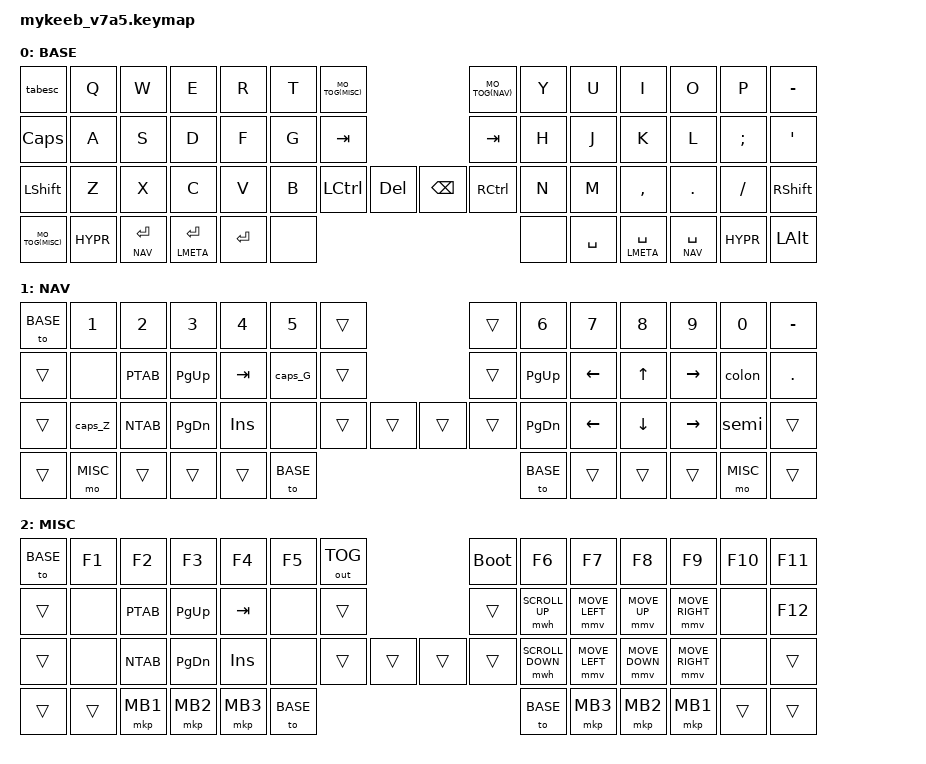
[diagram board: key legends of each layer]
#include <behaviors.dtsi>
#include <dt-bindings/zmk/keys.h>
#include <dt-bindings/zmk/bt.h>
#include <dt-bindings/zmk/outputs.h>
#include <dt-bindings/zmk/mouse.h>


//┏━━━━━━━━━━━━━━━━━━━━━━━━━━━━━━━━━━━━━━━━━━━━━━━━━━━━━━━━━━━━━━━━━━━━━━━━━━━━━━┓
//┃    this is expecting NEO 2.0 layout to be configured                         ┃
//┃    - it has some 7th row keys, to allow for y and ß                          ┃
//┃    - especially the macros for special characters use caps as an modifier    ┃
//┗━━━━━━━━━━━━━━━━━━━━━━━━━━━━━━━━━━━━━━━━━━━━━━━━━━━━━━━━━━━━━━━━━━━━━━━━━━━━━━┛


//┏━━━━━━━━━━━━━━━━━━━━━━━━━━━━━━━━━━━━━━━━━━━━━━━━━━━━━━━━━━━━━━━━━━━━━━━━━━━━━━┓
//┃    defines and macros                                                        ┃
#define PTAB LC(PG_UP)
#define NTAB LC(PG_DN)
// KC_MEH 		Left Control, Shift and Alt
#define MEH  LC(LS(LALT))
// KC_HYPR 		Left Control, Shift, Alt and GUI
#define HYPR LC(LS(LA(LGUI)))

// Macro to apply momentary-layer-on-hold/toggle-layer-on-tap to a specific layer
#define MO_TOG(layer) &mo_tog layer layer

#define CAPS_MACRO(name,key) \
    name: name { \
            label = ZMK_MACRO_STRINGIFY(ZM_ ## name); \
            compatible = "zmk,behavior-macro"; \
            #binding-cells = <0>; \
            bindings = <&macro_press &kp CAPS> , <&macro_tap &kp key >  , <&macro_release &kp CAPS> ; \
        };

#define XXX &none
#define ___ &trans
//┗━━━━━━━━━━━━━━━━━━━━━━━━━━━━━━━━━━━━━━━━━━━━━━━━━━━━━━━━━━━━━━━━━━━━━━━━━━━━━━┛

//┏━━━━━━━━━━━━━━━━━━━━━━━━━━━━━━━━━━━━━━━━━━━━━━━━━━━━━━━━━━━━━━━━━━━━━━━━━━━━━━┓
//┃    mouse stuff                                                               ┃
//┃    based on  https://github.com/urob/zmk-config/blob/main/config/mouse.dtsi  ┃
&mmv {
  acceleration-exponent = <1>;      // 1
  time-to-max-speed-ms = <1500>;    // 40
  delay-ms = <0>;                   // 0
};

&mwh {
  acceleration-exponent = <1>;      // 0
  time-to-max-speed-ms = <5000>;    // 40
  delay-ms = <0>;                   // 10
};

#define U_MOUSE_MOVE_MAX 1250       // 600
#define U_MOUSE_SCROLL_MAX 100      // 10

#undef MOVE_UP
#undef MOVE_DOWN
#undef MOVE_LEFT
#undef MOVE_RIGHT
#define MOVE_UP MOVE_VERT(-U_MOUSE_MOVE_MAX)
#define MOVE_DOWN MOVE_VERT(U_MOUSE_MOVE_MAX)
#define MOVE_LEFT MOVE_HOR(-U_MOUSE_MOVE_MAX)
#define MOVE_RIGHT MOVE_HOR(U_MOUSE_MOVE_MAX)

#undef SCROLL_UP
#undef SCROLL_DOWN
#undef SCROLL_LEFT
#undef SCROLL_RIGHT
#define SCROLL_UP SCROLL_VERT(U_MOUSE_SCROLL_MAX)
#define SCROLL_DOWN SCROLL_VERT(-U_MOUSE_SCROLL_MAX)
#define SCROLL_LEFT SCROLL_HOR(-U_MOUSE_SCROLL_MAX)
#define SCROLL_RIGHT SCROLL_HOR(U_MOUSE_SCROLL_MAX)

#define U_BTN1 &mkp MB1
#define U_BTN2 &mkp MB2
#define U_BTN3 &mkp MB3
#define U_MS_U &mmv MOVE_UP
#define U_MS_D &mmv MOVE_DOWN
#define U_MS_L &mmv MOVE_LEFT
#define U_MS_R &mmv MOVE_RIGHT
#define U_WH_U &mwh SCROLL_UP
#define U_WH_D &mwh SCROLL_DOWN
#define U_WH_L &mwh SCROLL_LEFT
#define U_WH_R &mwh SCROLL_RIGHT
//┗━━━━━━━━━━━━━━━━━━━━━━━━━━━━━━━━━━━━━━━━━━━━━━━━━━━━━━━━━━━━━━━━━━━━━━━━━━━━━━┛

//┏━━━━━━━━━━━━━━━━━━━━━━━━━━━━━━━━━━━━━━━━━━━━━━━━━━━━━━━━━━━━━━━━━━━━━━━━━━━━━━┓
//┃    layers                                                                    ┃
#define BASE 0
#define NAV  1
#define MISC 2
// #define SYMB 3
//┗━━━━━━━━━━━━━━━━━━━━━━━━━━━━━━━━━━━━━━━━━━━━━━━━━━━━━━━━━━━━━━━━━━━━━━━━━━━━━━┛

&sl {
    release-after-ms = <2000>;
};

/ {
    behaviors {
        // This is mod-tap with the "balanced" flavor.
        // Improves the '&mt RCTRL SPACE' behavior when typing quickly.
        bmt: balanced_mod_tap {
            compatible = "zmk,behavior-hold-tap";
            label = "MOD_TAP";
            #binding-cells = <2>;
            flavor = "balanced";
            tapping-term-ms = <200>;
            bindings = <&kp>, <&kp>;
        };
        skq: sticky_key_quick_release {
            compatible = "zmk,behavior-sticky-key";
            label = "STICKY_KEY_QUICK_RELEASE";
            #binding-cells = <1>;
            bindings = <&kp>;
            release-after-ms = <1000>;
            quick-release;
            ignore-modifiers;
        };
        mo_tog: behavior_mo_tog {
            compatible = "zmk,behavior-hold-tap";
            label = "mo_tog";
            #binding-cells = <2>;
            flavor = "hold-preferred";
            tapping-term-ms = <200>;
            bindings = <&mo>, <&tog>;
        };
        tabesc: tab_escape {
            compatible = "zmk,behavior-mod-morph";
            label = "TAB_ESCAPE";
            #binding-cells = <0>;
            bindings = <&kp ESC>, <&kp TAB>;
            mods = <(MOD_LGUI|MOD_LSFT|MOD_RGUI|MOD_RSFT)>;
        };
    };

    macros {
        CAPS_MACRO(caps_Q, Q)
        CAPS_MACRO(caps_W, W)
        CAPS_MACRO(caps_E, E)
        CAPS_MACRO(caps_R, R)
        CAPS_MACRO(caps_T, T)
        CAPS_MACRO(caps_Y, Y)
        CAPS_MACRO(caps_U, U)
        CAPS_MACRO(caps_I, I)
        CAPS_MACRO(caps_O, O)
        CAPS_MACRO(caps_P, P)

        CAPS_MACRO(caps_A, A)
        CAPS_MACRO(caps_S, S)
        CAPS_MACRO(caps_D, D)
        CAPS_MACRO(caps_F, F)
        CAPS_MACRO(caps_G, G)
        CAPS_MACRO(caps_H, H)
        CAPS_MACRO(caps_J, J)
        CAPS_MACRO(caps_K, K)
        CAPS_MACRO(caps_L, L)
        CAPS_MACRO(colon, SEMI)
        CAPS_MACRO(caps_SQT, SQT)

        CAPS_MACRO(caps_Z, Z)
        CAPS_MACRO(caps_X, X)
        CAPS_MACRO(caps_C, C)
        CAPS_MACRO(caps_V, V)
        CAPS_MACRO(caps_B, B)
        CAPS_MACRO(caps_N, N)
        CAPS_MACRO(caps_M, M)
        CAPS_MACRO(quote, COMMA)
        CAPS_MACRO(squote, DOT)
        CAPS_MACRO(semi, FSLH)
    };

    combos {
        compatible = "zmk,combos";
//┏━━━━━━━━━┳━━━━━━━━━━┳━━━━━━━━━━┳━━━━━━━━━━┳━━━━━━━━━━┳━━━━━━━━━━┳━━━━━━━━━━┓                             ┏━━━━━━━━━━┳━━━━━━━━━━┳━━━━━━━━━━┳━━━━━━━━━━┳━━━━━━━━━━┳━━━━━━━━━━┳━━━━━━━━━┓
// 0         1          2          3          4          5          6       /*┃*/                            7          8          9          10         11         12         13
// 14        15         16         17         18         19         20      /*┣━━━━━━━━━━┓       ┏━━━━━━━*/  21         22         23         24         25         26         27
// 28        29         30         31         32         33         34         35                 36         37         38         39         40         41         42         43
//┣━━━━━━━━━╋━━━┳━━━━━━┻━━━━━━━┳━━┻━━━━━━━━━━┻┳━━━━━━━━━┻━━━━┳━━━━━┻━━━━━━━━┳━┻━━━━━━━━━━┻━┓   ┏━┻━━━━━━━━━━┻━┳━━━━━━━━┻━━━━━┳━━━━┻━━━━━━━━━┳┻━━━━━━━━━━┻━━┳━━━━━━━┻━━━━━━┳━━━╋━━━━━━━━━┫
// 44            45             46             47             48             49                 50             51             52             53             54                 55
//┗━━━━━━━━━┛   ┗━━━━━━━━━━━━━━┻━━━━━━━━━━━━━━┻━━━━━━━━━━━━━━┻━━━━━━━━━━━━━━┻━━━━━━━━━━━━━━┛   ┗━━━━━━━━━━━━━━┻━━━━━━━━━━━━━━┻━━━━━━━━━━━━━━┻━━━━━━━━━━━━━━┻━━━━━━━━━━━━━━┛   ┗━━━━━━━━━┛
        combo_bootloader {
            timeout-ms = <100>;
            key-positions = <0 13>;
            bindings = <&bootloader>;
        };
        combo_bt_clear {
            timeout-ms = <100>;
            key-positions = <0 1 2 3 4>;
            bindings = <&bt BT_CLR>;
        };
        combo_ret {
            timeout-ms = <40>;
            key-positions = <46 47>;
            bindings = <&kp RET>;
        };
        combo_ret_2 {
            timeout-ms = <40>;
            key-positions = <47 48>;
            bindings = <&kp RET>;
        };
        combo_spc {
            timeout-ms = <40>;
            key-positions = <52 53>;
            bindings = <&kp SPC>;
        };
        combo_spc_2 {
            timeout-ms = <40>;
            key-positions = <51 52>;
            bindings = <&kp SPC>;
        };
        combo_ss {
            timeout-ms = <300>;
            key-positions = <14 13>;
            bindings = <&kp LEFT_BRACKET>;
        };
    };

    keymap {
        compatible = "zmk,keymap";

        base_layer {
            label= "BASE";
            bindings = <
//┏━━━━━━━━━┳━━━━━━━━━━┳━━━━━━━━━━┳━━━━━━━━━━┳━━━━━━━━━━┳━━━━━━━━━━┳━━━━━━━━━━┓                             ┏━━━━━━━━━━┳━━━━━━━━━━┳━━━━━━━━━━┳━━━━━━━━━━┳━━━━━━━━━━┳━━━━━━━━━━┳━━━━━━━━━┓
  &tabesc   &kp Q      &kp W      &kp E      &kp R      &kp T      MO_TOG(MISC)                             MO_TOG(NAV) &kp Y     &kp U      &kp I      &kp O      &kp P      &kp MINUS
  &kp CAPS  &kp A      &kp S      &kp D      &kp F      &kp G      &kp TAB  /*┣━━━━━━━━━━┓       ┏━━━━━━━*/ &kp TAB    &kp H      &kp J      &kp K      &kp L      &kp SEMI   &kp SQT
  &kp LSHFT &kp Z      &kp X      &kp C      &kp V      &kp B      &kp LCTRL  &kp DEL  /*┃*/     &kp BSPC   &kp RCTRL  &kp N      &kp M      &kp COMMA  &kp DOT    &kp FSLH   &kp RSHIFT
//┣━━━━━━━━━╋━━━┳━━━━━━┻━━━━━━━┳━━┻━━━━━━━━━━┻┳━━━━━━━━━┻━━━━┳━━━━━┻━━━━━━━━┳━┻━━━━━━━━━━┻━┓   ┏━┻━━━━━━━━━━┻━┳━━━━━━━━┻━━━━━┳━━━━┻━━━━━━━━━┳┻━━━━━━━━━━┻━━┳━━━━━━━┻━━━━━━┳━━━╋━━━━━━━━━┫
  MO_TOG(MISC)  &kp HYPR       &lt NAV RET    &bmt LMETA RET &kp RET        &none        /*┃*/ &none          &kp SPC        &bmt LMETA SPC &lt NAV SPC    &kp HYPR           &kp LALT
//┗━━━━━━━━━┛   ┗━━━━━━━━━━━━━━┻━━━━━━━━━━━━━━┻━━━━━━━━━━━━━━┻━━━━━━━━━━━━━━┻━━━━━━━━━━━━━━┛   ┗━━━━━━━━━━━━━━┻━━━━━━━━━━━━━━┻━━━━━━━━━━━━━━┻━━━━━━━━━━━━━━┻━━━━━━━━━━━━━━┛   ┗━━━━━━━━━┛
            >;
        };
        nav_layer {
            label= "NAV";
            bindings = <
//┏━━━━━━━━━┳━━━━━━━━━━┳━━━━━━━━━━┳━━━━━━━━━━┳━━━━━━━━━━┳━━━━━━━━━━┳━━━━━━━━━━┓                             ┏━━━━━━━━━━┳━━━━━━━━━━┳━━━━━━━━━━┳━━━━━━━━━━┳━━━━━━━━━━┳━━━━━━━━━━┳━━━━━━━━━┓
  &to BASE  &kp N1     &kp N2     &kp N3     &kp N4     &kp N5     ___      /*┃*/                           ___        &kp N6     &kp N7     &kp N8     &kp N9     &kp N0     &kp MINUS
  ___       XXX        &kp PTAB   &kp PG_UP  &kp TAB    &caps_G    ___      /*┣━━━━━━━━━━┓       ┏━━━━━━━*/ ___        &kp PG_UP  &kp LEFT   &kp UP     &kp RIGHT  &colon     &kp DOT
  ___       &caps_Z    &kp NTAB   &kp PG_DN  &kp INS    XXX        ___        ___      /*┃*/     ___        ___        &kp PG_DN  &kp LEFT   &kp DOWN   &kp RIGHT  &semi      ___   
//┣━━━━━━━━━╋━━━┳━━━━━━┻━━━━━━━┳━━┻━━━━━━━━━━┻┳━━━━━━━━━┻━━━━┳━━━━━┻━━━━━━━━┳━┻━━━━━━━━━━┻━┓   ┏━┻━━━━━━━━━━┻━┳━━━━━━━━┻━━━━━┳━━━━┻━━━━━━━━━┳┻━━━━━━━━━━┻━━┳━━━━━━━┻━━━━━━┳━━━╋━━━━━━━━━┫
  ___           &mo MISC       ___            ___            ___            &to BASE     /*┃*/ &to BASE       ___            ___            ___            &mo MISC           ___   
//┗━━━━━━━━━┛   ┗━━━━━━━━━━━━━━┻━━━━━━━━━━━━━━┻━━━━━━━━━━━━━━┻━━━━━━━━━━━━━━┻━━━━━━━━━━━━━━┛   ┗━━━━━━━━━━━━━━┻━━━━━━━━━━━━━━┻━━━━━━━━━━━━━━┻━━━━━━━━━━━━━━┻━━━━━━━━━━━━━━┛   ┗━━━━━━━━━┛
            >;
        };
        misc_layer {
            label= "MISC";
            bindings = <
//┏━━━━━━━━━┳━━━━━━━━━━┳━━━━━━━━━━┳━━━━━━━━━━┳━━━━━━━━━━┳━━━━━━━━━━┳━━━━━━━━━━┓                             ┏━━━━━━━━━━┳━━━━━━━━━━┳━━━━━━━━━━┳━━━━━━━━━━┳━━━━━━━━━━┳━━━━━━━━━━┳━━━━━━━━━┓
  &to BASE  &kp F1     &kp F2     &kp F3     &kp F4     &kp F5     &out OUT_TOG                             &bootloader &kp F6    &kp F7     &kp F8     &kp F9     &kp F10    &kp F11
  ___       XXX        &kp PTAB   &kp PG_UP  &kp TAB    XXX        ___      /*┣━━━━━━━━━━┓       ┏━━━━━━━*/ ___        U_WH_U     U_MS_L     U_MS_U     U_MS_R     XXX        &kp F12
  ___       XXX        &kp NTAB   &kp PG_DN  &kp INS    XXX        ___        ___      /*┃*/     ___        ___        U_WH_D     U_MS_L     U_MS_D     U_MS_R     XXX        ___   
//┣━━━━━━━━━╋━━━┳━━━━━━┻━━━━━━━┳━━┻━━━━━━━━━━┻┳━━━━━━━━━┻━━━━┳━━━━━┻━━━━━━━━┳━┻━━━━━━━━━━┻━┓   ┏━┻━━━━━━━━━━┻━┳━━━━━━━━┻━━━━━┳━━━━┻━━━━━━━━━┳┻━━━━━━━━━━┻━━┳━━━━━━━┻━━━━━━┳━━━╋━━━━━━━━━┫
  ___           ___            U_BTN1         U_BTN2         U_BTN3         &to BASE     /*┃*/ &to BASE       U_BTN3         U_BTN2         U_BTN1         ___                ___   
//┗━━━━━━━━━┛   ┗━━━━━━━━━━━━━━┻━━━━━━━━━━━━━━┻━━━━━━━━━━━━━━┻━━━━━━━━━━━━━━┻━━━━━━━━━━━━━━┛   ┗━━━━━━━━━━━━━━┻━━━━━━━━━━━━━━┻━━━━━━━━━━━━━━┻━━━━━━━━━━━━━━┻━━━━━━━━━━━━━━┛   ┗━━━━━━━━━┛
            >;
        };
//         symb_layer {
//             label= "SYMB";
//             bindings = <
// //┏━━━━━━━━━┳━━━━━━━━━━┳━━━━━━━━━━┳━━━━━━━━━━┳━━━━━━━━━━┳━━━━━━━━━━┳━━━━━━━━━━┓                             ┏━━━━━━━━━━┳━━━━━━━━━━┳━━━━━━━━━━┳━━━━━━━━━━┳━━━━━━━━━━┳━━━━━━━━━━┳━━━━━━━━━┓
//   ___       &caps_Q    &caps_W    &caps_E    &caps_R    &caps_T    ___      /*┃*/                           ___        &caps_Y    &caps_U    &caps_I    &caps_O    &caps_P    ___   
//   ___       &caps_A    &caps_S    &caps_D    &caps_F    &caps_G    ___      /*┣━━━━━━━━━━┓       ┏━━━━━━━*/ ___        &caps_H    &caps_J    &caps_K    &caps_L    &colon     &caps_ST
//   ___       &caps_Z    &caps_X    &caps_C    &caps_V    &caps_B    ___        ___      /*┃*/     ___        ___        &caps_N    &caps_M    &quote     &squote    &semi      ___   
// //┣━━━━━━━━━╋━━━┳━━━━━━┻━━━━━━━┳━━┻━━━━━━━━━━┻┳━━━━━━━━━┻━━━━┳━━━━━┻━━━━━━━━┳━┻━━━━━━━━━━┻━┓   ┏━┻━━━━━━━━━━┻━┳━━━━━━━━┻━━━━━┳━━━━┻━━━━━━━━━┳┻━━━━━━━━━━┻━━┳━━━━━━━┻━━━━━━┳━━━╋━━━━━━━━━┫
//   ___           ___            ___            ___            ___            &to BASE           &to BASE       ___            ___            ___            ___                ___   
// //┗━━━━━━━━━┛   ┗━━━━━━━━━━━━━━┻━━━━━━━━━━━━━━┻━━━━━━━━━━━━━━┻━━━━━━━━━━━━━━┻━━━━━━━━━━━━━━┛   ┗━━━━━━━━━━━━━━┻━━━━━━━━━━━━━━┻━━━━━━━━━━━━━━┻━━━━━━━━━━━━━━┻━━━━━━━━━━━━━━┛   ┗━━━━━━━━━┛
//             >;
//         };
    };
};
